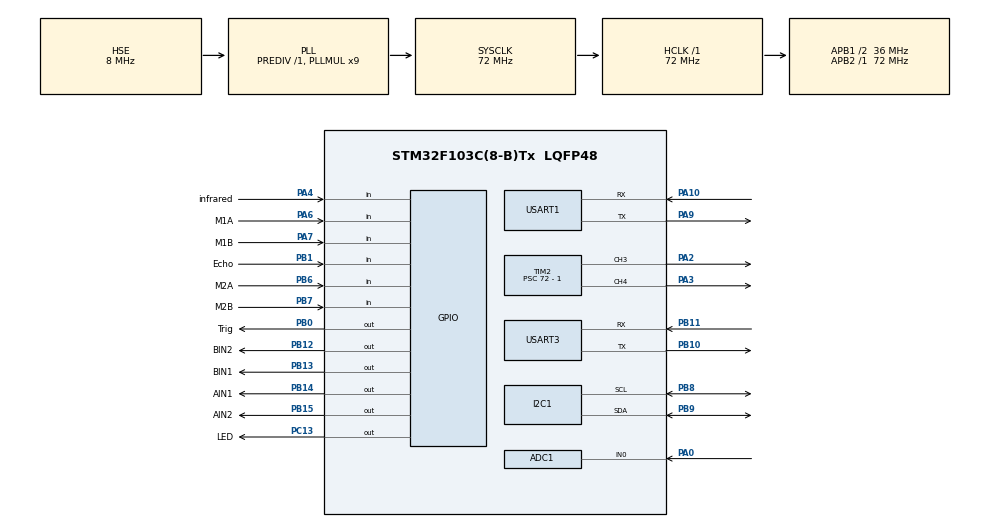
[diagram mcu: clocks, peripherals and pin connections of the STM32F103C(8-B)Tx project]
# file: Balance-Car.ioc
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ADC1.Channel-0\#ChannelRegularConversion=ADC_CHANNEL_0
ADC1.NbrOfConversionFlag=1
ADC1.Rank-0\#ChannelRegularConversion=1
ADC1.SamplingTime-0\#ChannelRegularConversion=ADC_SAMPLETIME_1CYCLE_5
ADC1.master=1
I2C1.I2C_Mode=I2C_Fast
Mcu.Family=STM32F1
Mcu.Name=STM32F103C(8-B)Tx
Mcu.Package=LQFP48
NVIC.PriorityGroup=NVIC_PRIORITYGROUP_4
NVIC.TIM3_IRQn=true\:0\:0\:false\:false\:true\:true\:true\:true
PA0-WKUP.Signal=ADCx_IN0
PA10.Mode=Asynchronous
PA10.Signal=USART1_RX
PA13.Mode=Serial_Wire
PA13.Signal=SYS_JTMS-SWDIO
PA14.Mode=Serial_Wire
PA14.Signal=SYS_JTCK-SWCLK
PA2.Signal=S_TIM2_CH3
PA3.Signal=S_TIM2_CH4
PA4.GPIO_Label=infrared
PA4.Signal=GPIO_Input
PA6.GPIO_Label=M1A
PA6.Signal=GPIO_Input
PA7.GPIO_Label=M1B
PA7.Signal=GPIO_Input
PA9.Mode=Asynchronous
PA9.Signal=USART1_TX
PB0.GPIO_Label=Trig
PB0.Signal=GPIO_Output
PB1.GPIO_Label=Echo
PB1.Signal=GPIO_Input
PB10.Mode=Asynchronous
PB10.Signal=USART3_TX
PB11.Mode=Asynchronous
PB11.Signal=USART3_RX
PB12.GPIO_Label=BIN2
PB12.Signal=GPIO_Output
PB13.GPIO_Label=BIN1
PB13.Signal=GPIO_Output
PB14.GPIO_Label=AIN1
PB14.Signal=GPIO_Output
PB15.GPIO_Label=AIN2
PB15.Signal=GPIO_Output
PB6.GPIO_Label=M2A
PB6.Signal=GPIO_Input
PB7.GPIO_Label=M2B
PB7.Signal=GPIO_Input
PB8.Mode=I2C
PB8.Signal=I2C1_SCL
PB9.Mode=I2C
PB9.Signal=I2C1_SDA
PC13-TAMPER-RTC.GPIO_Label=LED
PC13-TAMPER-RTC.Signal=GPIO_Output
PD0-OSC_IN.Mode=HSE-External-Oscillator
PD0-OSC_IN.Signal=RCC_OSC_IN
PD1-OSC_OUT.Mode=HSE-External-Oscillator
PD1-OSC_OUT.Signal=RCC_OSC_OUT
ProjectManager.HeapSize=0x200
ProjectManager.StackSize=0x400
ProjectManager.TargetToolchain=Makefile
RCC.ADCPresc=RCC_ADCPCLK2_DIV6
RCC.AHBFreq_Value=72000000
RCC.APB1CLKDivider=RCC_HCLK_DIV2
RCC.APB1Freq_Value=36000000
RCC.APB1TimFreq_Value=72000000
RCC.APB2Freq_Value=72000000
RCC.APB2TimFreq_Value=72000000
RCC.HCLKFreq_Value=72000000
RCC.PLLMUL=RCC_PLL_MUL9
RCC.PLLSourceVirtual=RCC_PLLSOURCE_HSE
RCC.SYSCLKFreq_VALUE=72000000
RCC.SYSCLKSource=RCC_SYSCLKSOURCE_PLLCLK
RCC.USBFreq_Value=72000000
SH.ADCx_IN0.0=ADC1_IN0,IN0
SH.S_TIM2_CH3.0=TIM2_CH3,PWM Generation3 CH3
SH.S_TIM2_CH4.0=TIM2_CH4,PWM Generation4 CH4
TIM2.Channel-PWM\ Generation3\ CH3=TIM_CHANNEL_3
TIM2.Channel-PWM\ Generation4\ CH4=TIM_CHANNEL_4
TIM2.Period=100
TIM2.Prescaler=72 - 1
TIM3.Period=65535
TIM3.Prescaler=72 - 1
USART1.VirtualMode=VM_ASYNC
USART3.VirtualMode=VM_ASYNC
VP_ADC1_Vref_Input.Mode=IN-Vrefint
VP_TIM3_VS_ClockSourceINT.Mode=Internal
board=custom

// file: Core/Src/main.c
/* USER CODE BEGIN Header */
/**
 ******************************************************************************
 * @file           : main.c
 * @brief          : Main program body
 ******************************************************************************
 * @attention
 *
 * Copyright (c) 2024 STMicroelectronics.
 * All rights reserved.
 *
 * This software is licensed under terms that can be found in the LICENSE file
 * in the root directory of this software component.
 * If no LICENSE file comes with this software, it is provided AS-IS.
 *
 ******************************************************************************
 */
/* USER CODE END Header */
#include "main.h"
#include "adc.h"
#include "i2c.h"
#include "tim.h"
#include "usart.h"
#include "gpio.h"

/* USER CODE BEGIN Includes */
#include <stdio.h>	// use sprintf
#include <string.h> // use strlen

#include "hc-sr04.h"
/* USER CODE END Includes */

void SystemClock_Config(void);

int main(void)
{

	/* MCU Configuration--------------------------------------------------------*/

	/* Reset of all peripherals, Initializes the Flash interface and the Systick. */
	HAL_Init();

	/* Configure the system clock */
	SystemClock_Config();

	/* Initialize all configured peripherals */
	MX_GPIO_Init();
	MX_USART3_UART_Init();
	MX_ADC1_Init();
	MX_I2C1_Init();
	MX_TIM2_Init();
	MX_USART1_UART_Init();
	MX_TIM3_Init();

	/* Infinite loop */
	/* USER CODE BEGIN WHILE */
	while (1)
	{
		char str[100];
		int distance = get_distance();
		sprintf(str, "Distance: %d cm\r\n", distance);
		HAL_UART_Transmit(&huart1, (uint8_t *)str, strlen(str), HAL_MAX_DELAY);

		HAL_Delay(100);

		/* USER CODE END WHILE */

	}
}

void SystemClock_Config(void)
{
	RCC_OscInitTypeDef RCC_OscInitStruct = {0};
	RCC_ClkInitTypeDef RCC_ClkInitStruct = {0};
	RCC_PeriphCLKInitTypeDef PeriphClkInit = {0};

	/** Initializes the RCC Oscillators according to the specified parameters
	 * in the RCC_OscInitTypeDef structure.
	 */
	RCC_OscInitStruct.OscillatorType = RCC_OSCILLATORTYPE_HSE;
	RCC_OscInitStruct.HSEState = RCC_HSE_ON;
	RCC_OscInitStruct.HSEPredivValue = RCC_HSE_PREDIV_DIV1;
	RCC_OscInitStruct.HSIState = RCC_HSI_ON;
	RCC_OscInitStruct.PLL.PLLState = RCC_PLL_ON;
	RCC_OscInitStruct.PLL.PLLSource = RCC_PLLSOURCE_HSE;
	RCC_OscInitStruct.PLL.PLLMUL = RCC_PLL_MUL9;
	if (HAL_RCC_OscConfig(&RCC_OscInitStruct) != HAL_OK)
	{
		Error_Handler();
	}

	/** Initializes the CPU, AHB and APB buses clocks
	 */
	RCC_ClkInitStruct.ClockType = RCC_CLOCKTYPE_HCLK | RCC_CLOCKTYPE_SYSCLK | RCC_CLOCKTYPE_PCLK1 | RCC_CLOCKTYPE_PCLK2;
	RCC_ClkInitStruct.SYSCLKSource = RCC_SYSCLKSOURCE_PLLCLK;
	RCC_ClkInitStruct.AHBCLKDivider = RCC_SYSCLK_DIV1;
	RCC_ClkInitStruct.APB1CLKDivider = RCC_HCLK_DIV2;
	RCC_ClkInitStruct.APB2CLKDivider = RCC_HCLK_DIV1;

	if (HAL_RCC_ClockConfig(&RCC_ClkInitStruct, FLASH_LATENCY_2) != HAL_OK)
	{
		Error_Handler();
	}
	PeriphClkInit.PeriphClockSelection = RCC_PERIPHCLK_ADC;
	PeriphClkInit.AdcClockSelection = RCC_ADCPCLK2_DIV6;
	if (HAL_RCCEx_PeriphCLKConfig(&PeriphClkInit) != HAL_OK)
	{
		Error_Handler();
	}
}

void Error_Handler(void)
{
	__disable_irq();
	while (1)
	{
	}
}
